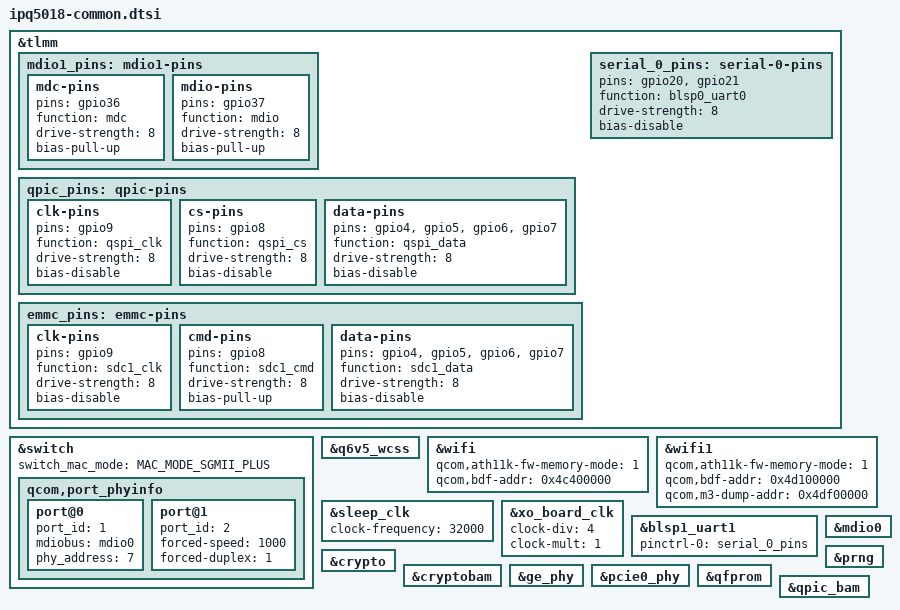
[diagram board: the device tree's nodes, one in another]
// SPDX-License-Identifier: GPL-2.0-or-later OR MIT

/*
 * ==================================================================
 *     _______________________             _______________________
 *    |        IPQ5018        |           |        QCA8337        |
 *    | +------+   +--------+ |           | +--------+   +------+ |
 *    | | MAC0 |---| GE Phy | |           | |  Phy0  |---| MAC1 | |
 *    | +------+   +--------+ |           | +--------+   +------+ |
 *    | +------+   +--------+ |           | +--------+   +------+ |
 *    | | MAC1 |---| Uniphy | +-- SGMII --+ | SerDes |---| MAC6 | |
 *    | +------+   +--------+ |           | +--------+   +------+ |
 *    |_______________________|           |_______________________|
 *
 * ==================================================================
 *     _______________________             _______________________
 *    |        IPQ5018        |           |        QCA8337        |
 *    | +------+   +--------+ |           | +--------+   +------+ |
 *    | | MAC0 |---| GE Phy | +--- MDI ---+ | Phy4   |---| MAC5 | |
 *    | +------+   +--------+ |           | +--------+   +------+ |
 *    |                       |           |_______________________|
 *    |                       |            _______________________
 *    |                       |           |        QCA8081        |
 *    | +------+   +--------+ |           | +--------+   +------+ |
 *    | | MAC1 |---| Uniphy | +-- SGMII --+ | Phy    |---| MAC  | |
 *    | +------+   +--------+ |           | +--------+   +------+ |
 *    |_______________________|           |_______________________|
 *
 * ==================================================================
 *
 * +------------+------+--------------+--------------+
 * | Argument   | type | def val UPD2 | def val UPD3 |
 * +------------+------+--------------+--------------+
 * | PCIE Index | u32  | 0x02 (PCIE1) | 0x01 (PCIE0) |
 * | Length     | u32  | 0x04         | 0x04         |
 * | User PD ID | u32  | 0x02         | 0x03         |
 * | Reset GPIO | u32  | 0x12         | 0x0f         |
 * | Reserved 1 | u32  | 0x00         | 0x00         |
 * | Reserved 2 | u32  | 0x00         | 0x00         |
 * +------------+------+--------------+--------------+
 *
 * On IPQ5018/QCN6122 boards, the default mapping is as follows:
 *
 *           +-> UPD1 ----> IPQ5018 Internal 2.4G Radio
 *          /
 *         /
 * Root PD +---> UPD2 ----> QCN6122 6G Radio on PCIE1 (if available)
 *         \
 *          \
 *           +-> UPD3 ----> QCN6102 5G Radio on PCIE0
 *
 * ==================================================================
 */

#include "ipq5018-qcn6122.dtsi"

#include <dt-bindings/gpio/gpio.h>
#include <dt-bindings/input/input.h>
#include <dt-bindings/leds/common.h>

&tlmm {
	mdio1_pins: mdio1-pins {
		mdc-pins {
			pins = "gpio36";
			function = "mdc";
			drive-strength = <8>;
			bias-pull-up;
		};

		mdio-pins {
			pins = "gpio37";
			function = "mdio";
			drive-strength = <8>;
			bias-pull-up;
		};
	};

	qpic_pins: qpic-pins {
		clk-pins {
			pins = "gpio9";
			function = "qspi_clk";
			drive-strength = <8>;
			bias-disable;
		};

		cs-pins {
			pins = "gpio8";
			function = "qspi_cs";
			drive-strength = <8>;
			bias-disable;
		};

		data-pins {
			pins = "gpio4", "gpio5", "gpio6", "gpio7";
			function = "qspi_data";
			drive-strength = <8>;
			bias-disable;
		};
	};

	emmc_pins: emmc-pins {
		clk-pins {
			pins = "gpio9";
			function = "sdc1_clk";
			drive-strength = <8>;
			bias-disable;
		};

		cmd-pins {
			pins = "gpio8";
			function = "sdc1_cmd";
			drive-strength = <8>;
			bias-pull-up;
		};

		data-pins {
			pins = "gpio4", "gpio5", "gpio6", "gpio7";
			function = "sdc1_data";
			drive-strength = <8>;
			bias-disable;
		};
	};

	serial_0_pins: serial-0-pins {
		pins = "gpio20", "gpio21";
		function = "blsp0_uart0";
		drive-strength = <8>;
		bias-disable;
	};
};

&switch {
	status = "okay";

	switch_mac_mode = <MAC_MODE_SGMII_PLUS>;

	qcom,port_phyinfo {
		// MAC0 -> GE Phy --- MDI --- QCA8337 Switch
		port@0 {
			port_id = <1>;
			mdiobus = <&mdio0>;
			phy_address = <7>;
		};

		// MAC1 ---SGMII---> QCA8337 SerDes
		port@1 {
			port_id = <2>;
			forced-speed = <1000>;
			forced-duplex = <1>;
		};
	};
};

&q6v5_wcss {
	status = "okay";
};

&wifi {
	status = "okay";

	qcom,ath11k-fw-memory-mode = <1>;
	qcom,bdf-addr = <0x4c400000>;
};

&wifi1 {
	status = "okay";

	qcom,ath11k-fw-memory-mode = <1>;
	qcom,bdf-addr = <0x4d100000>;
	qcom,m3-dump-addr = <0x4df00000>;
};

&sleep_clk {
	clock-frequency = <32000>;
};

&xo_board_clk {
	clock-div = <4>;
	clock-mult = <1>;
};

&blsp1_uart1 {
	status = "okay";

	pinctrl-0 = <&serial_0_pins>;
	pinctrl-names = "default";
};

&mdio0 {
	status = "okay";
};

&crypto {
	status = "okay";
};

&cryptobam {
	status = "okay";
};

&ge_phy {
	status = "okay";
};

&pcie0_phy {
	status = "okay";
};

&prng {
	status = "okay";
};

&qfprom {
	status = "okay";
};

&qpic_bam {
	status = "okay";
};
